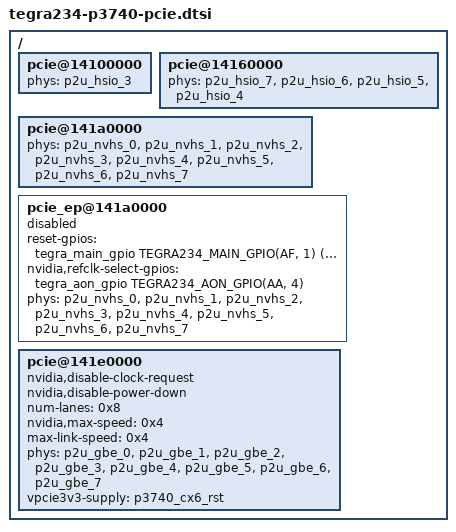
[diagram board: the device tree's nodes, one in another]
/*
 * Copyright (c) 2021, NVIDIA CORPORATION.  All rights reserved.
 *
 * This program is free software; you can redistribute it and/or modify
 * it under the terms of the GNU General Public License as published by
 * the Free Software Foundation; version 2 of the License.
 *
 * This program is distributed in the hope that it will be useful, but WITHOUT
 * ANY WARRANTY; without even the implied warranty of MERCHANTABILITY or
 * FITNESS FOR A PARTICULAR PURPOSE.  See the GNU General Public License for
 * more details.
 */

#include <dt-bindings/gpio/tegra234-gpio.h>

/ {

	pcie@14100000 {
		status = "okay";

		phys = <&p2u_hsio_3>;
		phy-names = "p2u-0";
	};

	pcie@14160000 {
		status = "okay";

		phys = <&p2u_hsio_7>, <&p2u_hsio_6>, <&p2u_hsio_5>,
		       <&p2u_hsio_4>;
		phy-names = "p2u-0", "p2u-1", "p2u-2", "p2u-3";
	};

	pcie@141a0000 {
		status = "okay";

		phys = <&p2u_nvhs_0>, <&p2u_nvhs_1>, <&p2u_nvhs_2>,
		       <&p2u_nvhs_3>, <&p2u_nvhs_4>, <&p2u_nvhs_5>,
		       <&p2u_nvhs_6>, <&p2u_nvhs_7>;
		phy-names = "p2u-0", "p2u-1", "p2u-2", "p2u-3", "p2u-4",
			    "p2u-5", "p2u-6", "p2u-7";
	};

	pcie_ep@141a0000 {
		status = "disabled";

		reset-gpios = <&tegra_main_gpio
			       TEGRA234_MAIN_GPIO(AF, 1)
			       GPIO_ACTIVE_LOW>;

		nvidia,refclk-select-gpios = <&tegra_aon_gpio
					      TEGRA234_AON_GPIO(AA, 4)
					      GPIO_ACTIVE_HIGH>;

		phys = <&p2u_nvhs_0>, <&p2u_nvhs_1>, <&p2u_nvhs_2>,
		       <&p2u_nvhs_3>, <&p2u_nvhs_4>, <&p2u_nvhs_5>,
		       <&p2u_nvhs_6>, <&p2u_nvhs_7>;
		phy-names = "p2u-0", "p2u-1", "p2u-2", "p2u-3", "p2u-4",
			    "p2u-5", "p2u-6", "p2u-7";
	};

	/* PCIe-C7: CX6 interface */
	pcie@141e0000 {
		status = "okay";

		nvidia,disable-clock-request;
		nvidia,disable-power-down;

		num-lanes = <0x8>;
		nvidia,max-speed = <0x4>;
		max-link-speed = <0x4>;

		phys = <&p2u_gbe_0>, <&p2u_gbe_1>, <&p2u_gbe_2>,
		       <&p2u_gbe_3>, <&p2u_gbe_4>, <&p2u_gbe_5>,
		       <&p2u_gbe_6>, <&p2u_gbe_7>;
		phy-names = "p2u-0", "p2u-1", "p2u-2", "p2u-3", "p2u-4",
			    "p2u-5", "p2u-6", "p2u-7";
		vpcie3v3-supply = <&p3740_cx6_rst>;
	};

};
